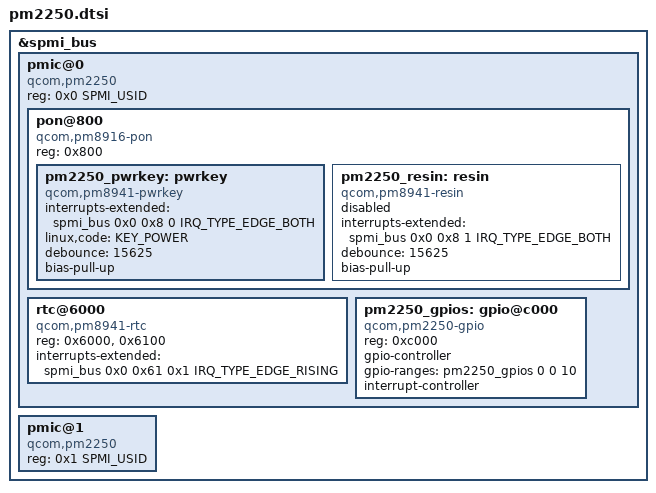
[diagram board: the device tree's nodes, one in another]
// SPDX-License-Identifier: (GPL-2.0+ OR BSD-3-Clause)
/*
 * Copyright (c) 2023, Linaro Ltd
 */

#include <dt-bindings/iio/qcom,spmi-vadc.h>
#include <dt-bindings/input/input.h>
#include <dt-bindings/interrupt-controller/irq.h>
#include <dt-bindings/spmi/spmi.h>

&spmi_bus {
	pmic@0 {
		compatible = "qcom,pm2250", "qcom,spmi-pmic";
		reg = <0x0 SPMI_USID>;
		#address-cells = <1>;
		#size-cells = <0>;

		pon@800 {
			compatible = "qcom,pm8916-pon";
			reg = <0x800>;

			pm2250_pwrkey: pwrkey {
				compatible = "qcom,pm8941-pwrkey";
				interrupts-extended = <&spmi_bus 0x0 0x8 0 IRQ_TYPE_EDGE_BOTH>;
				linux,code = <KEY_POWER>;
				debounce = <15625>;
				bias-pull-up;
			};

			pm2250_resin: resin {
				compatible = "qcom,pm8941-resin";
				interrupts-extended = <&spmi_bus 0x0 0x8 1 IRQ_TYPE_EDGE_BOTH>;
				debounce = <15625>;
				bias-pull-up;
				status = "disabled";
			};
		};

		rtc@6000 {
			compatible = "qcom,pm8941-rtc";
			reg = <0x6000>, <0x6100>;
			reg-names = "rtc", "alarm";
			interrupts-extended = <&spmi_bus 0x0 0x61 0x1 IRQ_TYPE_EDGE_RISING>;
		};

		pm2250_gpios: gpio@c000 {
			compatible = "qcom,pm2250-gpio", "qcom,spmi-gpio";
			reg = <0xc000>;
			gpio-controller;
			gpio-ranges = <&pm2250_gpios 0 0 10>;
			#gpio-cells = <2>;
			interrupt-controller;
			#interrupt-cells = <2>;
		};
	};

	pmic@1 {
		compatible = "qcom,pm2250", "qcom,spmi-pmic";
		reg = <0x1 SPMI_USID>;
		#address-cells = <1>;
		#size-cells = <0>;
	};
};
